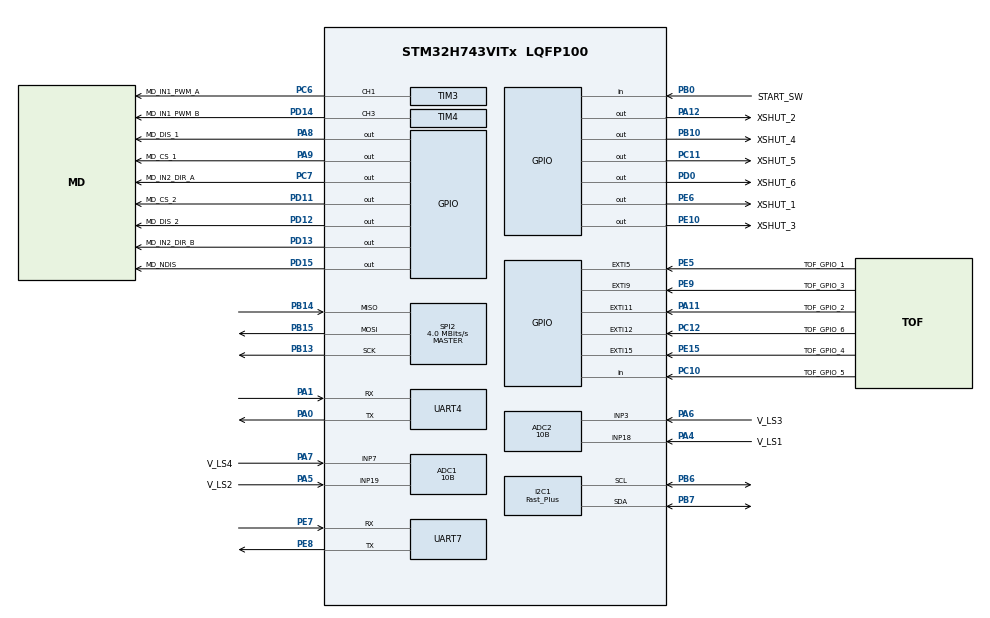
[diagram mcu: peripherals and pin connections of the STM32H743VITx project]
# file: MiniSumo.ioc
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ADC1.Channel-5\#ChannelRegularConversion=ADC_CHANNEL_7
ADC1.Channel-6\#ChannelRegularConversion=ADC_CHANNEL_19
ADC1.ClockPrescaler=ADC_CLOCK_ASYNC_DIV8
ADC1.ContinuousConvMode=ENABLE
ADC1.ConversionDataManagement=ADC_CONVERSIONDATA_DMA_CIRCULAR
ADC1.LeftBitShift=ADC_LEFTBITSHIFT_NONE
ADC1.NbrOfConversion=2
ADC1.NbrOfConversionFlag=1
ADC1.OffsetNumber-5\#ChannelRegularConversion=ADC_OFFSET_NONE
ADC1.OffsetNumber-6\#ChannelRegularConversion=ADC_OFFSET_NONE
ADC1.OffsetSignedSaturation-5\#ChannelRegularConversion=DISABLE
ADC1.Rank-5\#ChannelRegularConversion=1
ADC1.Rank-6\#ChannelRegularConversion=2
ADC1.Resolution=ADC_RESOLUTION_10B
ADC1.SamplingTime-5\#ChannelRegularConversion=ADC_SAMPLETIME_387CYCLES_5
ADC1.SamplingTime-6\#ChannelRegularConversion=ADC_SAMPLETIME_387CYCLES_5
ADC1.master=1
ADC2.Channel-0\#ChannelRegularConversion=ADC_CHANNEL_3
ADC2.Channel-1\#ChannelRegularConversion=ADC_CHANNEL_18
ADC2.ClockPrescaler=ADC_CLOCK_ASYNC_DIV8
ADC2.ContinuousConvMode=ENABLE
ADC2.ConversionDataManagement=ADC_CONVERSIONDATA_DMA_CIRCULAR
ADC2.NbrOfConversion=2
ADC2.NbrOfConversionFlag=1
ADC2.OffsetNumber-0\#ChannelRegularConversion=ADC_OFFSET_NONE
ADC2.OffsetNumber-1\#ChannelRegularConversion=ADC_OFFSET_NONE
ADC2.OffsetSignedSaturation-0\#ChannelRegularConversion=DISABLE
ADC2.Overrun=ADC_OVR_DATA_OVERWRITTEN
ADC2.Rank-0\#ChannelRegularConversion=1
ADC2.Rank-1\#ChannelRegularConversion=2
ADC2.Resolution=ADC_RESOLUTION_10B
ADC2.SamplingTime-0\#ChannelRegularConversion=ADC_SAMPLETIME_387CYCLES_5
ADC2.SamplingTime-1\#ChannelRegularConversion=ADC_SAMPLETIME_387CYCLES_5
Dma.ADC1.2.Direction=DMA_PERIPH_TO_MEMORY
Dma.ADC1.2.EventEnable=DISABLE
Dma.ADC1.2.FIFOMode=DMA_FIFOMODE_DISABLE
Dma.ADC1.2.Instance=DMA1_Stream1
Dma.ADC1.2.MemDataAlignment=DMA_MDATAALIGN_WORD
Dma.ADC1.2.MemInc=DMA_MINC_ENABLE
Dma.ADC1.2.Mode=DMA_CIRCULAR
Dma.ADC1.2.PeriphDataAlignment=DMA_PDATAALIGN_WORD
Dma.ADC1.2.PeriphInc=DMA_PINC_DISABLE
Dma.ADC1.2.Polarity=HAL_DMAMUX_REQ_GEN_RISING
Dma.ADC1.2.Priority=DMA_PRIORITY_LOW
Dma.ADC1.2.RequestNumber=1
Dma.ADC1.2.SignalID=NONE
Dma.ADC1.2.SyncEnable=DISABLE
Dma.ADC1.2.SyncPolarity=HAL_DMAMUX_SYNC_NO_EVENT
Dma.ADC1.2.SyncRequestNumber=1
Dma.ADC1.2.SyncSignalID=NONE
Dma.ADC2.1.Direction=DMA_PERIPH_TO_MEMORY
Dma.ADC2.1.EventEnable=DISABLE
Dma.ADC2.1.FIFOMode=DMA_FIFOMODE_DISABLE
Dma.ADC2.1.Instance=DMA1_Stream2
Dma.ADC2.1.MemDataAlignment=DMA_MDATAALIGN_WORD
Dma.ADC2.1.MemInc=DMA_MINC_ENABLE
Dma.ADC2.1.Mode=DMA_CIRCULAR
Dma.ADC2.1.PeriphDataAlignment=DMA_PDATAALIGN_WORD
Dma.ADC2.1.PeriphInc=DMA_PINC_DISABLE
Dma.ADC2.1.Polarity=HAL_DMAMUX_REQ_GEN_RISING
Dma.ADC2.1.Priority=DMA_PRIORITY_LOW
Dma.ADC2.1.RequestNumber=1
Dma.ADC2.1.SignalID=NONE
Dma.ADC2.1.SyncEnable=DISABLE
Dma.ADC2.1.SyncPolarity=HAL_DMAMUX_SYNC_NO_EVENT
Dma.ADC2.1.SyncRequestNumber=1
Dma.ADC2.1.SyncSignalID=NONE
Dma.Request0=UART7_RX
Dma.Request1=ADC2
Dma.Request2=ADC1
Dma.UART7_RX.0.Direction=DMA_PERIPH_TO_MEMORY
Dma.UART7_RX.0.EventEnable=DISABLE
Dma.UART7_RX.0.FIFOMode=DMA_FIFOMODE_DISABLE
Dma.UART7_RX.0.Instance=DMA1_Stream0
Dma.UART7_RX.0.MemDataAlignment=DMA_MDATAALIGN_BYTE
Dma.UART7_RX.0.MemInc=DMA_MINC_ENABLE
Dma.UART7_RX.0.Mode=DMA_NORMAL
Dma.UART7_RX.0.PeriphDataAlignment=DMA_PDATAALIGN_BYTE
Dma.UART7_RX.0.PeriphInc=DMA_PINC_DISABLE
Dma.UART7_RX.0.Polarity=HAL_DMAMUX_REQ_GEN_RISING
Dma.UART7_RX.0.Priority=DMA_PRIORITY_HIGH
Dma.UART7_RX.0.RequestNumber=1
Dma.UART7_RX.0.SignalID=NONE
Dma.UART7_RX.0.SyncEnable=DISABLE
Dma.UART7_RX.0.SyncPolarity=HAL_DMAMUX_SYNC_NO_EVENT
Dma.UART7_RX.0.SyncRequestNumber=1
Dma.UART7_RX.0.SyncSignalID=NONE
FREERTOS.Tasks01=defaultTask,24,1024,StartDefaultTask,Default,NULL,Dynamic,NULL,NULL
FREERTOS.configMINIMAL_STACK_SIZE=512
FREERTOS.configTOTAL_HEAP_SIZE=30720
FREERTOS.configUSE_NEWLIB_REENTRANT=1
FREERTOS.configUSE_PREEMPTION=1
I2C1.I2C_Speed_Mode=I2C_Fast_Plus
I2C1.Timing=0x0050174F
Mcu.Family=STM32H7
Mcu.Name=STM32H743VITx
Mcu.Package=LQFP100
NVIC.DMA1_Stream0_IRQn=true\:5\:0\:false\:true\:true\:7\:true\:false\:true\:true
NVIC.DMA1_Stream1_IRQn=true\:5\:0\:false\:true\:true\:6\:true\:false\:true\:true
NVIC.DMA1_Stream2_IRQn=true\:5\:0\:false\:true\:true\:5\:true\:false\:true\:true
NVIC.EXTI15_10_IRQn=true\:5\:0\:false\:true\:true\:3\:true\:true\:true\:true
NVIC.EXTI9_5_IRQn=true\:5\:0\:false\:true\:true\:4\:true\:true\:true\:true
NVIC.I2C1_EV_IRQn=true\:5\:0\:false\:true\:true\:10\:true\:true\:true\:true
NVIC.PriorityGroup=NVIC_PRIORITYGROUP_4
NVIC.RCC_IRQn=true\:5\:0\:false\:false\:true\:true\:true\:false\:true
NVIC.SPI2_IRQn=true\:5\:0\:false\:true\:true\:2\:true\:true\:true\:true
NVIC.TIM1_UP_IRQn=true\:4\:0\:true\:false\:true\:false\:false\:true\:true
NVIC.TIM3_IRQn=true\:5\:0\:false\:true\:true\:9\:true\:true\:true\:true
NVIC.TIM4_IRQn=true\:5\:0\:false\:true\:true\:8\:true\:true\:true\:true
NVIC.TimeBase=TIM1_UP_IRQn
NVIC.TimeBaseIP=TIM1
NVIC.UART7_IRQn=true\:5\:0\:false\:true\:true\:1\:true\:true\:true\:true
PA0.Mode=Asynchronous
PA0.Signal=UART4_TX
PA1.Mode=Asynchronous
PA1.PinAttribute=Free
PA1.Signal=UART4_RX
PA11.GPIO_Label=TOF_GPIO_2
PA11.Signal=GPXTI11
PA12.GPIO_Label=XSHUT_2
PA12.PinState=GPIO_PIN_SET
PA12.Signal=GPIO_Output
PA13\ (JTMS/SWDIO).Mode=Trace_Asynchronous_SW
PA13\ (JTMS/SWDIO).Signal=DEBUG_JTMS-SWDIO
PA14\ (JTCK/SWCLK).Mode=Trace_Asynchronous_SW
PA14\ (JTCK/SWCLK).Signal=DEBUG_JTCK-SWCLK
PA4.GPIO_Label=V_LS1
PA4.PinAttribute=Free
PA4.Signal=ADCx_INP18
PA5.GPIO_Label=V_LS2
PA5.PinAttribute=Free
PA5.Signal=ADCx_INP19
PA6.GPIO_Label=V_LS3
PA6.Signal=ADCx_INP3
PA7.GPIO_Label=V_LS4
PA7.Signal=ADCx_INP7
PA8.GPIO_Label=MD_DIS_1
PA8.GPIO_PuPd=GPIO_PULLUP
PA8.GPIO_Speed=GPIO_SPEED_FREQ_MEDIUM
PA8.PinState=GPIO_PIN_SET
PA8.Signal=GPIO_Output
PA9.GPIO_Label=MD_CS_1
PA9.GPIO_ModeDefaultOutputPP=GPIO_MODE_OUTPUT_PP
PA9.GPIO_PuPd=GPIO_PULLUP
PA9.PinState=GPIO_PIN_SET
PA9.Signal=GPIO_Output
PB0.GPIO_Label=START_SW
PB0.PinAttribute=Free
PB0.Signal=GPIO_Input
PB10.GPIO_Label=XSHUT_4
PB10.Signal=GPIO_Output
PB13.GPIO_Speed=GPIO_SPEED_FREQ_VERY_HIGH
PB13.Mode=Full_Duplex_Master
PB13.Signal=SPI2_SCK
PB14.GPIO_Speed=GPIO_SPEED_FREQ_VERY_HIGH
PB14.Mode=Full_Duplex_Master
PB14.Signal=SPI2_MISO
PB15.GPIO_Speed=GPIO_SPEED_FREQ_VERY_HIGH
PB15.Mode=Full_Duplex_Master
PB15.Signal=SPI2_MOSI
PB3\ (JTDO/TRACESWO).Mode=Trace_Asynchronous_SW
PB3\ (JTDO/TRACESWO).Signal=DEBUG_JTDO-SWO
PB6.GPIO_Pu=GPIO_PULLUP
PB6.Mode=I2C
PB6.Signal=I2C1_SCL
PB7.GPIO_Pu=GPIO_PULLUP
PB7.Mode=I2C
PB7.Signal=I2C1_SDA
PC10.GPIO_Label=TOF_GPIO_5
PC10.Signal=GPIO_Input
PC11.GPIO_Label=XSHUT_5
PC11.PinState=GPIO_PIN_RESET
PC11.Signal=GPIO_Output
PC12.GPIO_Label=TOF_GPIO_6
PC12.Signal=GPXTI12
PC6.GPIO_Label=MD_IN1_PWM_A
PC6.Signal=S_TIM3_CH1
PC7.GPIO_Label=MD_IN2_DIR_A
PC7.Signal=GPIO_Output
PD0.GPIO_Label=XSHUT_6
PD0.Signal=GPIO_Output
PD11.GPIO_Label=MD_CS_2
PD11.GPIO_ModeDefaultOutputPP=GPIO_MODE_OUTPUT_PP
PD11.GPIO_PuPd=GPIO_PULLUP
PD11.PinState=GPIO_PIN_SET
PD11.Signal=GPIO_Output
PD12.GPIO_Label=MD_DIS_2
PD12.GPIO_PuPd=GPIO_PULLUP
PD12.PinState=GPIO_PIN_SET
PD12.Signal=GPIO_Output
PD13.GPIO_Label=MD_IN2_DIR_B
PD13.Signal=GPIO_Output
PD14.GPIO_Label=MD_IN1_PWM_B
PD14.Signal=S_TIM4_CH3
PD15.GPIO_Label=MD_NDIS
PD15.GPIO_ModeDefaultOutputPP=GPIO_MODE_OUTPUT_PP
PD15.GPIO_PuPd=GPIO_NOPULL
PD15.GPIO_Speed=GPIO_SPEED_FREQ_VERY_HIGH
PD15.PinState=GPIO_PIN_SET
PD15.Signal=GPIO_Output
PE10.GPIO_Label=XSHUT_3
PE10.Signal=GPIO_Output
PE15.GPIO_Label=TOF_GPIO_4
PE15.Signal=GPXTI15
PE5.GPIO_Label=TOF_GPIO_1
PE5.Signal=GPXTI5
PE6.GPIO_Label=XSHUT_1
PE6.PinState=GPIO_PIN_SET
PE6.Signal=GPIO_Output
PE7.Mode=Asynchronous
PE7.PinAttribute=Free
PE7.Signal=UART7_RX
PE8.Mode=Asynchronous
PE8.PinAttribute=Free
PE8.Signal=UART7_TX
PE9.GPIO_Label=TOF_GPIO_3
PE9.PinAttribute=Free
PE9.Signal=GPXTI9
PH0-OSC_IN\ (PH0).Mode=HSE-External-Clock-Source
PH0-OSC_IN\ (PH0).Signal=RCC_OSC_IN
ProjectManager.HeapSize=0x400
ProjectManager.StackSize=0x800
ProjectManager.TargetToolchain=STM32CubeIDE
RCC.ADCCLockSelection=RCC_ADCCLKSOURCE_PLL3
RCC.ADCFreq_Value=75000000
RCC.APB1Freq_Value=120000000
RCC.APB2Freq_Value=120000000
RCC.APB3Freq_Value=120000000
RCC.APB4Freq_Value=120000000
RCC.CortexFreq_Value=480000000
RCC.D1PPRE=RCC_APB3_DIV2
RCC.D2PPRE1=RCC_APB1_DIV2
RCC.D2PPRE2=RCC_APB2_DIV2
RCC.D3PPRE=RCC_APB4_DIV2
RCC.DIVM1=3
RCC.DIVM2=3
RCC.DIVM3=2
RCC.DIVN1=120
RCC.DIVN2=32
RCC.DIVN3=12
RCC.DIVQ1=4
RCC.DIVQ2=1
RCC.DIVQ3=1
RCC.DIVR1=8
RCC.DIVR2=1
RCC.HCLKFreq_Value=240000000
RCC.HPRE=RCC_HCLK_DIV2
RCC.HSE_VALUE=24000000
RCC.PLL1_VCI_Range-AdvancedSettings=RCC_PLL1VCIRANGE_0
RCC.PLL1_VCO_SEL-AdvancedSettings=RCC_PLL1VCOMEDIUM
RCC.PLL2FRACN=0
RCC.PLL2_VCI_Range-AdvancedSettings=RCC_PLL2VCIRANGE_0
RCC.PLL2_VCO_SEL-AdvancedSettings=RCC_PLL2VCOMEDIUM
RCC.PLL3FRACN=4096
RCC.PLL3_VCI_Range-AdvancedSettings=RCC_PLL3VCIRANGE_1
RCC.PLL3_VCO_SEL-AdvancedSettings=RCC_PLL3VCOMEDIUM
RCC.PLLFRACN=0
RCC.PLLSourceVirtual=RCC_PLLSOURCE_HSE
RCC.PWR_Regulator_Voltage_Scale=PWR_REGULATOR_VOLTAGE_SCALE0
RCC.ProductRev=revV
RCC.SPI123CLockSelection=RCC_SPI123CLKSOURCE_PLL2
RCC.SYSCLKFreq_VALUE=480000000
RCC.SYSCLKSource=RCC_SYSCLKSOURCE_PLLCLK
RCC.USBFreq_Value=240000000
SH.ADCx_INP18.0=ADC2_INP18,IN18-Single-Ended
SH.ADCx_INP18.1=ADC1_INP18
SH.ADCx_INP19.0=ADC1_INP19,IN19-Single-Ended
SH.ADCx_INP3.0=ADC1_INP3
SH.ADCx_INP3.1=ADC2_INP3,IN3-Single-Ended
SH.ADCx_INP7.0=ADC1_INP7,IN7-Single-Ended
SH.S_TIM3_CH1.0=TIM3_CH1,PWM Generation1 CH1
SH.S_TIM4_CH3.0=TIM4_CH3,PWM Generation3 CH3
SPI2.BaudRatePrescaler=SPI_BAUDRATEPRESCALER_32
SPI2.CLKPhase=SPI_PHASE_2EDGE
SPI2.CLKPolarity=SPI_POLARITY_LOW
SPI2.CRCCalculation=SPI_CRCCALCULATION_DISABLE
SPI2.CalculateBaudRate=4.0 MBits/s
SPI2.DataSize=SPI_DATASIZE_8BIT
SPI2.Direction=SPI_DIRECTION_2LINES
SPI2.MasterKeepIOState=SPI_MASTER_KEEP_IO_STATE_ENABLE
SPI2.Mode=SPI_MODE_MASTER
SPI2.VirtualType=VM_MASTER
TIM3.Channel-PWM\ Generation1\ CH1=TIM_CHANNEL_1
TIM3.Period=999
TIM3.Prescaler=100
TIM4.Channel-PWM\ Generation3\ CH3=TIM_CHANNEL_3
TIM4.Period=999
TIM4.Prescaler=100
VP_FREERTOS_VS_CMSIS_V2.Mode=CMSIS_V2
VP_SYS_VS_tim1.Mode=TIM1
board=custom

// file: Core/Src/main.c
/* USER CODE BEGIN Header */
/**
  ******************************************************************************
  * @file           : main.c
  * @brief          : Main program body
  ******************************************************************************
  * @attention
  *
  * <h2><center>&copy; Copyright (c) 2021 STMicroelectronics.
  * All rights reserved.</center></h2>
  *
  * This software component is licensed by ST under BSD 3-Clause license,
  * the "License"; You may not use this file except in compliance with the
  * License. You may obtain a copy of the License at:
  *                        opensource.org/licenses/BSD-3-Clause
  *
  ******************************************************************************
  */
/* USER CODE END Header */
#include "main.h"
#include "cmsis_os.h"

/* USER CODE BEGIN Includes */
#include "EntryCPP.hpp"
/* USER CODE END Includes */

ADC_HandleTypeDef hadc1;
ADC_HandleTypeDef hadc2;
DMA_HandleTypeDef hdma_adc1;
DMA_HandleTypeDef hdma_adc2;

I2C_HandleTypeDef hi2c1;

SPI_HandleTypeDef hspi2;

TIM_HandleTypeDef htim3;
TIM_HandleTypeDef htim4;

UART_HandleTypeDef huart4;
UART_HandleTypeDef huart7;
DMA_HandleTypeDef hdma_uart7_rx;

/* Definitions for defaultTask */
osThreadId_t defaultTaskHandle;
const osThreadAttr_t defaultTask_attributes = {
  .name = "defaultTask",
  .stack_size = 1024 * 4,
  .priority = (osPriority_t) osPriorityNormal,
};

void SystemClock_Config(void);
void PeriphCommonClock_Config(void);
static void MX_GPIO_Init(void);
static void MX_DMA_Init(void);
static void MX_ADC2_Init(void);
static void MX_I2C1_Init(void);
static void MX_SPI2_Init(void);
static void MX_UART4_Init(void);
static void MX_UART7_Init(void);
static void MX_ADC1_Init(void);
static void MX_TIM3_Init(void);
static void MX_TIM4_Init(void);
void StartDefaultTask(void *argument);

static void MX_NVIC_Init(void);

int main(void)
{

  /* MCU Configuration--------------------------------------------------------*/

  /* Reset of all peripherals, Initializes the Flash interface and the Systick. */
  HAL_Init();

  /* Configure the system clock */
  SystemClock_Config();

/* Configure the peripherals common clocks */
  PeriphCommonClock_Config();

  /* Initialize all configured peripherals */
  MX_GPIO_Init();
  MX_DMA_Init();
  MX_ADC2_Init();
  MX_I2C1_Init();
  MX_SPI2_Init();
  MX_UART4_Init();
  MX_UART7_Init();
  MX_ADC1_Init();
  MX_TIM3_Init();
  MX_TIM4_Init();

  /* Initialize interrupts */
  MX_NVIC_Init();
  /* USER CODE BEGIN 2 */
//  InitSensors();
  HAL_UART_MspInit(&huart7);
  /* USER CODE END 2 */

  /* Init scheduler */
  osKernelInitialize();

  /* Create the thread(s) */
  /* creation of defaultTask */
  defaultTaskHandle = osThreadNew(StartDefaultTask, NULL, &defaultTask_attributes);

  /* USER CODE BEGIN RTOS_THREADS */
  /* add threads, ... */

//  TaskHandle_t xHandle = NULL;
//
//  /* Create the task, storing the handle. */
//  BaseType_t xReturned = xTaskCreate(
//    		  	  	  main_cpp,       /* Function that implements the task. */
//                      "NAME",          /* Text name for the task. */
//                      1024,      /* Stack size in words, not bytes. */
//                      ( void * ) 1,    /* Parameter passed into the task. */
//                      tskIDLE_PRIORITY,/* Priority at which the task is created. */
//                      &xHandle );
//  if(xReturned != pdPASS)
//  {
//	  Error_Handler();
//  }

  /* USER CODE END RTOS_THREADS */

  /* USER CODE BEGIN RTOS_EVENTS */
  /* add events, ... */
  //start robot
  main_cpp(NULL);

  /* USER CODE END RTOS_EVENTS */

  /* Start scheduler */
  osKernelStart();

  /* We should never get here as control is now taken by the scheduler */
  /* Infinite loop */
  while (1)
  {

  }
}

void SystemClock_Config(void)
{
  RCC_OscInitTypeDef RCC_OscInitStruct = {0};
  RCC_ClkInitTypeDef RCC_ClkInitStruct = {0};

  /** Supply configuration update enable
  */
  HAL_PWREx_ConfigSupply(PWR_LDO_SUPPLY);

  /** Configure the main internal regulator output voltage
  */
  __HAL_PWR_VOLTAGESCALING_CONFIG(PWR_REGULATOR_VOLTAGE_SCALE1);

  while(!__HAL_PWR_GET_FLAG(PWR_FLAG_VOSRDY)) {}

  __HAL_RCC_SYSCFG_CLK_ENABLE();
  __HAL_PWR_VOLTAGESCALING_CONFIG(PWR_REGULATOR_VOLTAGE_SCALE0);

  while(!__HAL_PWR_GET_FLAG(PWR_FLAG_VOSRDY)) {}

  /** Macro to configure the PLL clock source
  */
  __HAL_RCC_PLL_PLLSOURCE_CONFIG(RCC_PLLSOURCE_HSE);

  /** Initializes the RCC Oscillators according to the specified parameters
  * in the RCC_OscInitTypeDef structure.
  */
  RCC_OscInitStruct.OscillatorType = RCC_OSCILLATORTYPE_HSE;
  RCC_OscInitStruct.HSEState = RCC_HSE_BYPASS;
  RCC_OscInitStruct.PLL.PLLState = RCC_PLL_ON;
  RCC_OscInitStruct.PLL.PLLSource = RCC_PLLSOURCE_HSE;
  RCC_OscInitStruct.PLL.PLLM = 3;
  RCC_OscInitStruct.PLL.PLLN = 120;
  RCC_OscInitStruct.PLL.PLLP = 2;
  RCC_OscInitStruct.PLL.PLLQ = 4;
  RCC_OscInitStruct.PLL.PLLR = 8;
  RCC_OscInitStruct.PLL.PLLRGE = RCC_PLL1VCIRANGE_3;
  RCC_OscInitStruct.PLL.PLLVCOSEL = RCC_PLL1VCOWIDE;
  RCC_OscInitStruct.PLL.PLLFRACN = 0;
  if (HAL_RCC_OscConfig(&RCC_OscInitStruct) != HAL_OK)
  {
    Error_Handler();
  }

  /** Initializes the CPU, AHB and APB buses clocks
  */
  RCC_ClkInitStruct.ClockType = RCC_CLOCKTYPE_HCLK|RCC_CLOCKTYPE_SYSCLK
                              |RCC_CLOCKTYPE_PCLK1|RCC_CLOCKTYPE_PCLK2
                              |RCC_CLOCKTYPE_D3PCLK1|RCC_CLOCKTYPE_D1PCLK1;
  RCC_ClkInitStruct.SYSCLKSource = RCC_SYSCLKSOURCE_PLLCLK;
  RCC_ClkInitStruct.SYSCLKDivider = RCC_SYSCLK_DIV1;
  RCC_ClkInitStruct.AHBCLKDivider = RCC_HCLK_DIV2;
  RCC_ClkInitStruct.APB3CLKDivider = RCC_APB3_DIV2;
  RCC_ClkInitStruct.APB1CLKDivider = RCC_APB1_DIV2;
  RCC_ClkInitStruct.APB2CLKDivider = RCC_APB2_DIV2;
  RCC_ClkInitStruct.APB4CLKDivider = RCC_APB4_DIV2;

  if (HAL_RCC_ClockConfig(&RCC_ClkInitStruct, FLASH_LATENCY_4) != HAL_OK)
  {
    Error_Handler();
  }
}

void PeriphCommonClock_Config(void)
{
  RCC_PeriphCLKInitTypeDef PeriphClkInitStruct = {0};

  /** Initializes the peripherals clock
  */
  PeriphClkInitStruct.PeriphClockSelection = RCC_PERIPHCLK_ADC;
  PeriphClkInitStruct.PLL3.PLL3M = 2;
  PeriphClkInitStruct.PLL3.PLL3N = 12;
  PeriphClkInitStruct.PLL3.PLL3P = 2;
  PeriphClkInitStruct.PLL3.PLL3Q = 1;
  PeriphClkInitStruct.PLL3.PLL3R = 2;
  PeriphClkInitStruct.PLL3.PLL3RGE = RCC_PLL3VCIRANGE_3;
  PeriphClkInitStruct.PLL3.PLL3VCOSEL = RCC_PLL3VCOMEDIUM;
  PeriphClkInitStruct.PLL3.PLL3FRACN = 4096;
  PeriphClkInitStruct.AdcClockSelection = RCC_ADCCLKSOURCE_PLL3;
  if (HAL_RCCEx_PeriphCLKConfig(&PeriphClkInitStruct) != HAL_OK)
  {
    Error_Handler();
  }
}

/**
  * @brief NVIC Configuration.
  * @retval None
  */
static void MX_NVIC_Init(void)
{
  /* UART7_IRQn interrupt configuration */
  HAL_NVIC_SetPriority(UART7_IRQn, 5, 0);
  HAL_NVIC_EnableIRQ(UART7_IRQn);
  /* SPI2_IRQn interrupt configuration */
  HAL_NVIC_SetPriority(SPI2_IRQn, 5, 0);
  HAL_NVIC_EnableIRQ(SPI2_IRQn);
  /* EXTI15_10_IRQn interrupt configuration */
  HAL_NVIC_SetPriority(EXTI15_10_IRQn, 5, 0);
  HAL_NVIC_EnableIRQ(EXTI15_10_IRQn);
  /* EXTI9_5_IRQn interrupt configuration */
  HAL_NVIC_SetPriority(EXTI9_5_IRQn, 5, 0);
  HAL_NVIC_EnableIRQ(EXTI9_5_IRQn);
  /* DMA1_Stream2_IRQn interrupt configuration */
  HAL_NVIC_SetPriority(DMA1_Stream2_IRQn, 5, 0);
  HAL_NVIC_EnableIRQ(DMA1_Stream2_IRQn);
  /* DMA1_Stream1_IRQn interrupt configuration */
  HAL_NVIC_SetPriority(DMA1_Stream1_IRQn, 5, 0);
  HAL_NVIC_EnableIRQ(DMA1_Stream1_IRQn);
  /* DMA1_Stream0_IRQn interrupt configuration */
  HAL_NVIC_SetPriority(DMA1_Stream0_IRQn, 5, 0);
  HAL_NVIC_EnableIRQ(DMA1_Stream0_IRQn);
  /* TIM4_IRQn interrupt configuration */
  HAL_NVIC_SetPriority(TIM4_IRQn, 5, 0);
  HAL_NVIC_EnableIRQ(TIM4_IRQn);
  /* TIM3_IRQn interrupt configuration */
  HAL_NVIC_SetPriority(TIM3_IRQn, 5, 0);
  HAL_NVIC_EnableIRQ(TIM3_IRQn);
  /* I2C1_EV_IRQn interrupt configuration */
  HAL_NVIC_SetPriority(I2C1_EV_IRQn, 5, 0);
  HAL_NVIC_EnableIRQ(I2C1_EV_IRQn);
}

static void MX_ADC1_Init(void)
{

  ADC_MultiModeTypeDef multimode = {0};
  ADC_ChannelConfTypeDef sConfig = {0};

  /** Common config
  */
  hadc1.Instance = ADC1;
  hadc1.Init.ClockPrescaler = ADC_CLOCK_ASYNC_DIV8;
  hadc1.Init.Resolution = ADC_RESOLUTION_10B;
  hadc1.Init.ScanConvMode = ADC_SCAN_ENABLE;
  hadc1.Init.EOCSelection = ADC_EOC_SINGLE_CONV;
  hadc1.Init.LowPowerAutoWait = DISABLE;
  hadc1.Init.ContinuousConvMode = ENABLE;
  hadc1.Init.NbrOfConversion = 2;
  hadc1.Init.DiscontinuousConvMode = DISABLE;
  hadc1.Init.ExternalTrigConv = ADC_SOFTWARE_START;
  hadc1.Init.ExternalTrigConvEdge = ADC_EXTERNALTRIGCONVEDGE_NONE;
  hadc1.Init.ConversionDataManagement = ADC_CONVERSIONDATA_DMA_CIRCULAR;
  hadc1.Init.Overrun = ADC_OVR_DATA_PRESERVED;
  hadc1.Init.LeftBitShift = ADC_LEFTBITSHIFT_NONE;
  hadc1.Init.OversamplingMode = DISABLE;
  if (HAL_ADC_Init(&hadc1) != HAL_OK)
  {
    Error_Handler();
  }

  /** Configure the ADC multi-mode
  */
  multimode.Mode = ADC_MODE_INDEPENDENT;
  if (HAL_ADCEx_MultiModeConfigChannel(&hadc1, &multimode) != HAL_OK)
  {
    Error_Handler();
  }

  /** Configure Regular Channel
  */
  sConfig.Channel = ADC_CHANNEL_7;
  sConfig.Rank = ADC_REGULAR_RANK_1;
  sConfig.SamplingTime = ADC_SAMPLETIME_387CYCLES_5;
  sConfig.SingleDiff = ADC_SINGLE_ENDED;
  sConfig.OffsetNumber = ADC_OFFSET_NONE;
  sConfig.Offset = 0;
  sConfig.OffsetSignedSaturation = DISABLE;
  if (HAL_ADC_ConfigChannel(&hadc1, &sConfig) != HAL_OK)
  {
    Error_Handler();
  }

  /** Configure Regular Channel
  */
  sConfig.Channel = ADC_CHANNEL_19;
  sConfig.Rank = ADC_REGULAR_RANK_2;
  if (HAL_ADC_ConfigChannel(&hadc1, &sConfig) != HAL_OK)
  {
    Error_Handler();
  }

}

static void MX_ADC2_Init(void)
{

  ADC_ChannelConfTypeDef sConfig = {0};

  /** Common config
  */
  hadc2.Instance = ADC2;
  hadc2.Init.ClockPrescaler = ADC_CLOCK_ASYNC_DIV8;
  hadc2.Init.Resolution = ADC_RESOLUTION_10B;
  hadc2.Init.ScanConvMode = ADC_SCAN_ENABLE;
  hadc2.Init.EOCSelection = ADC_EOC_SINGLE_CONV;
  hadc2.Init.LowPowerAutoWait = DISABLE;
  hadc2.Init.ContinuousConvMode = ENABLE;
  hadc2.Init.NbrOfConversion = 2;
  hadc2.Init.DiscontinuousConvMode = DISABLE;
  hadc2.Init.ExternalTrigConv = ADC_SOFTWARE_START;
  hadc2.Init.ExternalTrigConvEdge = ADC_EXTERNALTRIGCONVEDGE_NONE;
  hadc2.Init.ConversionDataManagement = ADC_CONVERSIONDATA_DMA_CIRCULAR;
  hadc2.Init.Overrun = ADC_OVR_DATA_OVERWRITTEN;
  hadc2.Init.LeftBitShift = ADC_LEFTBITSHIFT_NONE;
  hadc2.Init.OversamplingMode = DISABLE;
  if (HAL_ADC_Init(&hadc2) != HAL_OK)
  {
    Error_Handler();
  }

  /** Configure Regular Channel
  */
  sConfig.Channel = ADC_CHANNEL_3;
  sConfig.Rank = ADC_REGULAR_RANK_1;
  sConfig.SamplingTime = ADC_SAMPLETIME_387CYCLES_5;
  sConfig.SingleDiff = ADC_SINGLE_ENDED;
  sConfig.OffsetNumber = ADC_OFFSET_NONE;
  sConfig.Offset = 0;
  sConfig.OffsetSignedSaturation = DISABLE;
  if (HAL_ADC_ConfigChannel(&hadc2, &sConfig) != HAL_OK)
  {
    Error_Handler();
  }

  /** Configure Regular Channel
  */
  sConfig.Channel = ADC_CHANNEL_18;
  sConfig.Rank = ADC_REGULAR_RANK_2;
  if (HAL_ADC_ConfigChannel(&hadc2, &sConfig) != HAL_OK)
  {
    Error_Handler();
  }

}

static void MX_I2C1_Init(void)
{

  hi2c1.Instance = I2C1;
  hi2c1.Init.Timing = 0x0050174F;
  hi2c1.Init.OwnAddress1 = 0;
  hi2c1.Init.AddressingMode = I2C_ADDRESSINGMODE_7BIT;
  hi2c1.Init.DualAddressMode = I2C_DUALADDRESS_DISABLE;
  hi2c1.Init.OwnAddress2 = 0;
  hi2c1.Init.OwnAddress2Masks = I2C_OA2_NOMASK;
  hi2c1.Init.GeneralCallMode = I2C_GENERALCALL_DISABLE;
  hi2c1.Init.NoStretchMode = I2C_NOSTRETCH_DISABLE;
  if (HAL_I2C_Init(&hi2c1) != HAL_OK)
  {
    Error_Handler();
  }

  /** Configure Analogue filter
  */
  if (HAL_I2CEx_ConfigAnalogFilter(&hi2c1, I2C_ANALOGFILTER_ENABLE) != HAL_OK)
  {
    Error_Handler();
  }

  /** Configure Digital filter
  */
  if (HAL_I2CEx_ConfigDigitalFilter(&hi2c1, 0) != HAL_OK)
  {
    Error_Handler();
  }

  /** I2C Enable Fast Mode Plus
  */
  HAL_I2CEx_EnableFastModePlus(I2C_FASTMODEPLUS_I2C1);

}

static void MX_SPI2_Init(void)
{

  /* SPI2 parameter configuration*/
  hspi2.Instance = SPI2;
  hspi2.Init.Mode = SPI_MODE_MASTER;
  hspi2.Init.Direction = SPI_DIRECTION_2LINES;
  hspi2.Init.DataSize = SPI_DATASIZE_8BIT;
  hspi2.Init.CLKPolarity = SPI_POLARITY_LOW;
  hspi2.Init.CLKPhase = SPI_PHASE_2EDGE;
  hspi2.Init.NSS = SPI_NSS_SOFT;
  hspi2.Init.BaudRatePrescaler = SPI_BAUDRATEPRESCALER_32;
  hspi2.Init.FirstBit = SPI_FIRSTBIT_MSB;
  hspi2.Init.TIMode = SPI_TIMODE_DISABLE;
  hspi2.Init.CRCCalculation = SPI_CRCCALCULATION_DISABLE;
  hspi2.Init.CRCPolynomial = 0x0;
  hspi2.Init.NSSPMode = SPI_NSS_PULSE_ENABLE;
  hspi2.Init.NSSPolarity = SPI_NSS_POLARITY_LOW;
  hspi2.Init.FifoThreshold = SPI_FIFO_THRESHOLD_01DATA;
  hspi2.Init.TxCRCInitializationPattern = SPI_CRC_INITIALIZATION_ALL_ZERO_PATTERN;
  hspi2.Init.RxCRCInitializationPattern = SPI_CRC_INITIALIZATION_ALL_ZERO_PATTERN;
  hspi2.Init.MasterSSIdleness = SPI_MASTER_SS_IDLENESS_00CYCLE;
  hspi2.Init.MasterInterDataIdleness = SPI_MASTER_INTERDATA_IDLENESS_00CYCLE;
  hspi2.Init.MasterReceiverAutoSusp = SPI_MASTER_RX_AUTOSUSP_DISABLE;
  hspi2.Init.MasterKeepIOState = SPI_MASTER_KEEP_IO_STATE_ENABLE;
  hspi2.Init.IOSwap = SPI_IO_SWAP_DISABLE;
  if (HAL_SPI_Init(&hspi2) != HAL_OK)
  {
    Error_Handler();
  }

}

static void MX_TIM3_Init(void)
{

  TIM_MasterConfigTypeDef sMasterConfig = {0};
  TIM_OC_InitTypeDef sConfigOC = {0};

  htim3.Instance = TIM3;
  htim3.Init.Prescaler = 100;
  htim3.Init.CounterMode = TIM_COUNTERMODE_UP;
  htim3.Init.Period = 999;
  htim3.Init.ClockDivision = TIM_CLOCKDIVISION_DIV1;
  htim3.Init.AutoReloadPreload = TIM_AUTORELOAD_PRELOAD_DISABLE;
  if (HAL_TIM_PWM_Init(&htim3) != HAL_OK)
  {
    Error_Handler();
  }
  sMasterConfig.MasterOutputTrigger = TIM_TRGO_RESET;
  sMasterConfig.MasterSlaveMode = TIM_MASTERSLAVEMODE_DISABLE;
  if (HAL_TIMEx_MasterConfigSynchronization(&htim3, &sMasterConfig) != HAL_OK)
  {
    Error_Handler();
  }
  sConfigOC.OCMode = TIM_OCMODE_PWM1;
  sConfigOC.Pulse = 0;
  sConfigOC.OCPolarity = TIM_OCPOLARITY_HIGH;
  sConfigOC.OCFastMode = TIM_OCFAST_DISABLE;
  if (HAL_TIM_PWM_ConfigChannel(&htim3, &sConfigOC, TIM_CHANNEL_1) != HAL_OK)
  {
    Error_Handler();
  }
  HAL_TIM_MspPostInit(&htim3);

}

static void MX_TIM4_Init(void)
{

  TIM_MasterConfigTypeDef sMasterConfig = {0};
  TIM_OC_InitTypeDef sConfigOC = {0};

  htim4.Instance = TIM4;
  htim4.Init.Prescaler = 100;
  htim4.Init.CounterMode = TIM_COUNTERMODE_UP;
  htim4.Init.Period = 999;
  htim4.Init.ClockDivision = TIM_CLOCKDIVISION_DIV1;
  htim4.Init.AutoReloadPreload = TIM_AUTORELOAD_PRELOAD_DISABLE;
  if (HAL_TIM_PWM_Init(&htim4) != HAL_OK)
  {
    Error_Handler();
  }
  sMasterConfig.MasterOutputTrigger = TIM_TRGO_RESET;
  sMasterConfig.MasterSlaveMode = TIM_MASTERSLAVEMODE_DISABLE;
  if (HAL_TIMEx_MasterConfigSynchronization(&htim4, &sMasterConfig) != HAL_OK)
  {
    Error_Handler();
  }
  sConfigOC.OCMode = TIM_OCMODE_PWM1;
  sConfigOC.Pulse = 0;
  sConfigOC.OCPolarity = TIM_OCPOLARITY_HIGH;
  sConfigOC.OCFastMode = TIM_OCFAST_DISABLE;
  if (HAL_TIM_PWM_ConfigChannel(&htim4, &sConfigOC, TIM_CHANNEL_3) != HAL_OK)
  {
    Error_Handler();
  }
  HAL_TIM_MspPostInit(&htim4);

}

static void MX_UART4_Init(void)
{

  huart4.Instance = UART4;
  huart4.Init.BaudRate = 115200;
  huart4.Init.WordLength = UART_WORDLENGTH_8B;
  huart4.Init.StopBits = UART_STOPBITS_1;
  huart4.Init.Parity = UART_PARITY_NONE;
  huart4.Init.Mode = UART_MODE_TX_RX;
  huart4.Init.HwFlowCtl = UART_HWCONTROL_NONE;
  huart4.Init.OverSampling = UART_OVERSAMPLING_16;
  huart4.Init.OneBitSampling = UART_ONE_BIT_SAMPLE_DISABLE;
  huart4.Init.ClockPrescaler = UART_PRESCALER_DIV1;
  huart4.AdvancedInit.AdvFeatureInit = UART_ADVFEATURE_NO_INIT;
  if (HAL_UART_Init(&huart4) != HAL_OK)
  {
    Error_Handler();
  }
  if (HAL_UARTEx_SetTxFifoThreshold(&huart4, UART_TXFIFO_THRESHOLD_1_8) != HAL_OK)
  {
    Error_Handler();
  }
  if (HAL_UARTEx_SetRxFifoThreshold(&huart4, UART_RXFIFO_THRESHOLD_1_8) != HAL_OK)
  {
    Error_Handler();
  }
  if (HAL_UARTEx_DisableFifoMode(&huart4) != HAL_OK)
  {
    Error_Handler();
  }

}

static void MX_UART7_Init(void)
{

  huart7.Instance = UART7;
  huart7.Init.BaudRate = 115200;
  huart7.Init.WordLength = UART_WORDLENGTH_8B;
  huart7.Init.StopBits = UART_STOPBITS_1;
  huart7.Init.Parity = UART_PARITY_NONE;
  huart7.Init.Mode = UART_MODE_TX_RX;
  huart7.Init.HwFlowCtl = UART_HWCONTROL_NONE;
  huart7.Init.OverSampling = UART_OVERSAMPLING_16;
  huart7.Init.OneBitSampling = UART_ONE_BIT_SAMPLE_DISABLE;
  huart7.Init.ClockPrescaler = UART_PRESCALER_DIV1;
  huart7.AdvancedInit.AdvFeatureInit = UART_ADVFEATURE_NO_INIT;
  if (HAL_UART_Init(&huart7) != HAL_OK)
  {
    Error_Handler();
  }
  if (HAL_UARTEx_SetTxFifoThreshold(&huart7, UART_TXFIFO_THRESHOLD_1_8) != HAL_OK)
  {
    Error_Handler();
  }
  if (HAL_UARTEx_SetRxFifoThreshold(&huart7, UART_RXFIFO_THRESHOLD_1_8) != HAL_OK)
  {
    Error_Handler();
  }
  if (HAL_UARTEx_DisableFifoMode(&huart7) != HAL_OK)
  {
    Error_Handler();
  }

}

static void MX_DMA_Init(void)
{

  /* DMA controller clock enable */
  __HAL_RCC_DMA1_CLK_ENABLE();

}

static void MX_GPIO_Init(void)
{
  GPIO_InitTypeDef GPIO_InitStruct = {0};

  /* GPIO Ports Clock Enable */
  __HAL_RCC_GPIOE_CLK_ENABLE();
  __HAL_RCC_GPIOH_CLK_ENABLE();
  __HAL_RCC_GPIOA_CLK_ENABLE();
  __HAL_RCC_GPIOB_CLK_ENABLE();
  __HAL_RCC_GPIOD_CLK_ENABLE();
  __HAL_RCC_GPIOC_CLK_ENABLE();

  /*Configure GPIO pin Output Level */
  HAL_GPIO_WritePin(XSHUT_1_GPIO_Port, XSHUT_1_Pin, GPIO_PIN_SET);

  /*Configure GPIO pin Output Level */
  HAL_GPIO_WritePin(XSHUT_3_GPIO_Port, XSHUT_3_Pin, GPIO_PIN_RESET);

  /*Configure GPIO pin Output Level */
  HAL_GPIO_WritePin(XSHUT_4_GPIO_Port, XSHUT_4_Pin, GPIO_PIN_RESET);

  /*Configure GPIO pin Output Level */
  HAL_GPIO_WritePin(GPIOD, MD_CS_2_Pin|MD_DIS_2_Pin|MD_NDIS_Pin, GPIO_PIN_SET);

  /*Configure GPIO pin Output Level */
  HAL_GPIO_WritePin(GPIOD, MD_IN2_DIR_B_Pin|XSHUT_6_Pin, GPIO_PIN_RESET);

  /*Configure GPIO pin Output Level */
  HAL_GPIO_WritePin(GPIOC, MD_IN2_DIR_A_Pin|XSHUT_5_Pin, GPIO_PIN_RESET);

  /*Configure GPIO pin Output Level */
  HAL_GPIO_WritePin(GPIOA, MD_DIS_1_Pin|MD_CS_1_Pin|XSHUT_2_Pin, GPIO_PIN_SET);

  /*Configure GPIO pins : TOF_GPIO_1_Pin TOF_GPIO_3_Pin TOF_GPIO_4_Pin */
  GPIO_InitStruct.Pin = TOF_GPIO_1_Pin|TOF_GPIO_3_Pin|TOF_GPIO_4_Pin;
  GPIO_InitStruct.Mode = GPIO_MODE_IT_RISING;
  GPIO_InitStruct.Pull = GPIO_NOPULL;
  HAL_GPIO_Init(GPIOE, &GPIO_InitStruct);

  /*Configure GPIO pins : XSHUT_1_Pin XSHUT_3_Pin */
  GPIO_InitStruct.Pin = XSHUT_1_Pin|XSHUT_3_Pin;
  GPIO_InitStruct.Mode = GPIO_MODE_OUTPUT_PP;
  GPIO_InitStruct.Pull = GPIO_NOPULL;
  GPIO_InitStruct.Speed = GPIO_SPEED_FREQ_LOW;
  HAL_GPIO_Init(GPIOE, &GPIO_InitStruct);

  /*Configure GPIO pin : START_SW_Pin */
  GPIO_InitStruct.Pin = START_SW_Pin;
  GPIO_InitStruct.Mode = GPIO_MODE_INPUT;
  GPIO_InitStruct.Pull = GPIO_NOPULL;
  HAL_GPIO_Init(START_SW_GPIO_Port, &GPIO_InitStruct);

  /*Configure GPIO pin : XSHUT_4_Pin */
  GPIO_InitStruct.Pin = XSHUT_4_Pin;
  GPIO_InitStruct.Mode = GPIO_MODE_OUTPUT_PP;
  GPIO_InitStruct.Pull = GPIO_NOPULL;
  GPIO_InitStruct.Speed = GPIO_SPEED_FREQ_LOW;
  HAL_GPIO_Init(XSHUT_4_GPIO_Port, &GPIO_InitStruct);

  /*Configure GPIO pins : MD_CS_2_Pin MD_DIS_2_Pin */
  GPIO_InitStruct.Pin = MD_CS_2_Pin|MD_DIS_2_Pin;
  GPIO_InitStruct.Mode = GPIO_MODE_OUTPUT_PP;
  GPIO_InitStruct.Pull = GPIO_PULLUP;
  GPIO_InitStruct.Speed = GPIO_SPEED_FREQ_LOW;
  HAL_GPIO_Init(GPIOD, &GPIO_InitStruct);

  /*Configure GPIO pins : MD_IN2_DIR_B_Pin XSHUT_6_Pin */
  GPIO_InitStruct.Pin = MD_IN2_DIR_B_Pin|XSHUT_6_Pin;
  GPIO_InitStruct.Mode = GPIO_MODE_OUTPUT_PP;
  GPIO_InitStruct.Pull = GPIO_NOPULL;
  GPIO_InitStruct.Speed = GPIO_SPEED_FREQ_LOW;
  HAL_GPIO_Init(GPIOD, &GPIO_InitStruct);

  /*Configure GPIO pin : MD_NDIS_Pin */
  GPIO_InitStruct.Pin = MD_NDIS_Pin;
  GPIO_InitStruct.Mode = GPIO_MODE_OUTPUT_PP;
  GPIO_InitStruct.Pull = GPIO_NOPULL;
  GPIO_InitStruct.Speed = GPIO_SPEED_FREQ_VERY_HIGH;
  HAL_GPIO_Init(MD_NDIS_GPIO_Port, &GPIO_InitStruct);

  /*Configure GPIO pins : MD_IN2_DIR_A_Pin XSHUT_5_Pin */
  GPIO_InitStruct.Pin = MD_IN2_DIR_A_Pin|XSHUT_5_Pin;
  GPIO_InitStruct.Mode = GPIO_MODE_OUTPUT_PP;
  GPIO_InitStruct.Pull = GPIO_NOPULL;
  GPIO_InitStruct.Speed = GPIO_SPEED_FREQ_LOW;
  HAL_GPIO_Init(GPIOC, &GPIO_InitStruct);

  /*Configure GPIO pin : MD_DIS_1_Pin */
  GPIO_InitStruct.Pin = MD_DIS_1_Pin;
  GPIO_InitStruct.Mode = GPIO_MODE_OUTPUT_PP;
  GPIO_InitStruct.Pull = GPIO_PULLUP;
  GPIO_InitStruct.Speed = GPIO_SPEED_FREQ_MEDIUM;
  HAL_GPIO_Init(MD_DIS_1_GPIO_Port, &GPIO_InitStruct);

  /*Configure GPIO pin : MD_CS_1_Pin */
  GPIO_InitStruct.Pin = MD_CS_1_Pin;
  GPIO_InitStruct.Mode = GPIO_MODE_OUTPUT_PP;
  GPIO_InitStruct.Pull = GPIO_PULLUP;
  GPIO_InitStruct.Speed = GPIO_SPEED_FREQ_LOW;
  HAL_GPIO_Init(MD_CS_1_GPIO_Port, &GPIO_InitStruct);

  /*Configure GPIO pin : TOF_GPIO_2_Pin */
  GPIO_InitStruct.Pin = TOF_GPIO_2_Pin;
  GPIO_InitStruct.Mode = GPIO_MODE_IT_RISING;
  GPIO_InitStruct.Pull = GPIO_NOPULL;
  HAL_GPIO_Init(TOF_GPIO_2_GPIO_Port, &GPIO_InitStruct);

  /*Configure GPIO pin : XSHUT_2_Pin */
  GPIO_InitStruct.Pin = XSHUT_2_Pin;
  GPIO_InitStruct.Mode = GPIO_MODE_OUTPUT_PP;
  GPIO_InitStruct.Pull = GPIO_NOPULL;
  GPIO_InitStruct.Speed = GPIO_SPEED_FREQ_LOW;
  HAL_GPIO_Init(XSHUT_2_GPIO_Port, &GPIO_InitStruct);

  /*Configure GPIO pin : TOF_GPIO_5_Pin */
  GPIO_InitStruct.Pin = TOF_GPIO_5_Pin;
  GPIO_InitStruct.Mode = GPIO_MODE_INPUT;
  GPIO_InitStruct.Pull = GPIO_NOPULL;
  HAL_GPIO_Init(TOF_GPIO_5_GPIO_Port, &GPIO_InitStruct);

  /*Configure GPIO pin : TOF_GPIO_6_Pin */
  GPIO_InitStruct.Pin = TOF_GPIO_6_Pin;
  GPIO_InitStruct.Mode = GPIO_MODE_IT_RISING;
  GPIO_InitStruct.Pull = GPIO_NOPULL;
  HAL_GPIO_Init(TOF_GPIO_6_GPIO_Port, &GPIO_InitStruct);

}

void StartDefaultTask(void *argument)
{
  for(;;)
  {
    osDelay(1);
  }
}

void HAL_TIM_PeriodElapsedCallback(TIM_HandleTypeDef *htim)
{
  if (htim->Instance == TIM1) {
    HAL_IncTick();
  }
}

void Error_Handler(void)
{
  __disable_irq();
  while (1)
  {
  }
}
